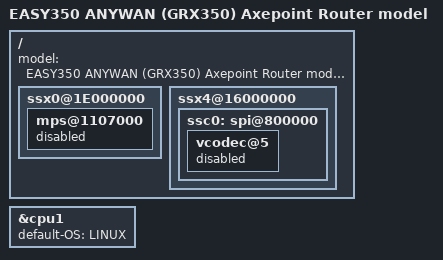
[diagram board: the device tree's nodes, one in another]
/*****************************************************************
** Include the main configuration file
*****************************************************************/
#include "easy350_anywan_axepoint.dts"

/ {
	model = "EASY350 ANYWAN (GRX350) Axepoint Router model";

	ssx0@1E000000 {
		mps@1107000 {
			status = "disabled";
		};
	};

	ssx4@16000000 {
		ssc0: spi@800000 {
			vcodec@5 {
				status = "disabled";
			};
		};
	};
};

/******************************************************************************
** Model configuration: Arrange specific FW to run on VPEs. 
******************************************************************************/
/* use CPU1 for Linux */
&cpu1 {
	default-OS = "LINUX";
};
